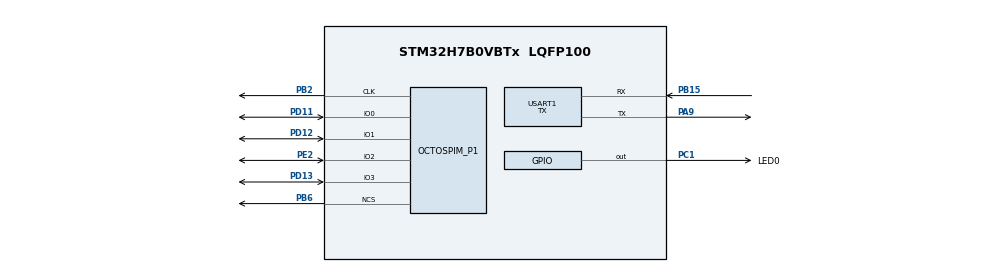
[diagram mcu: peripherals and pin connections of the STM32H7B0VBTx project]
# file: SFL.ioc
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CORTEX_M7.default_mode_Activation=1
Mcu.Family=STM32H7
Mcu.Name=STM32H7B0VBTx
Mcu.Package=LQFP100
NVIC.PriorityGroup=NVIC_PRIORITYGROUP_4
OCTOSPI1.ClockMode=HAL_OSPI_CLOCK_MODE_3
OCTOSPI1.ClockPrescaler=2
OCTOSPI1.DeviceSize=23
OCTOSPI1.FifoThreshold=8
OCTOSPI1.SampleShifting=HAL_OSPI_SAMPLE_SHIFTING_HALFCYCLE
PA13.Mode=Serial_Wire
PA13.Signal=DEBUG_JTMS-SWDIO
PA14.Mode=Serial_Wire
PA14.Signal=DEBUG_JTCK-SWCLK
PA9.Mode=Asynchronous
PA9.Signal=USART1_TX
PB15.Mode=Asynchronous
PB15.Signal=USART1_RX
PB2.Mode=O1_P1_CLK
PB2.Signal=OCTOSPIM_P1_CLK
PB6.Mode=OCTOSPI1_Port1_NCS
PB6.Signal=OCTOSPIM_P1_NCS
PC1.GPIO_Label=LED0
PC1.GPIO_Speed=GPIO_SPEED_FREQ_VERY_HIGH
PC1.PinState=GPIO_PIN_SET
PC1.Signal=GPIO_Output
PD11.Mode=OCTOSPI1_IOL_Port1L
PD11.Signal=OCTOSPIM_P1_IO0
PD12.Mode=OCTOSPI1_IOL_Port1L
PD12.Signal=OCTOSPIM_P1_IO1
PD13.Mode=OCTOSPI1_IOL_Port1L
PD13.Signal=OCTOSPIM_P1_IO3
PE2.Mode=OCTOSPI1_IOL_Port1L
PE2.Signal=OCTOSPIM_P1_IO2
PH0-OSC_IN.Mode=HSE-External-Oscillator
PH0-OSC_IN.Signal=RCC_OSC_IN
PH1-OSC_OUT.Mode=HSE-External-Oscillator
PH1-OSC_OUT.Signal=RCC_OSC_OUT
ProjectManager.HeapSize=0x200
ProjectManager.StackSize=0x400
ProjectManager.TargetToolchain=CMake
RCC.ADCFreq_Value=50390625
RCC.APB1Freq_Value=140000000
RCC.APB2Freq_Value=140000000
RCC.APB3Freq_Value=140000000
RCC.APB4Freq_Value=140000000
RCC.CDPPRE=RCC_APB3_DIV2
RCC.CDPPRE1=RCC_APB1_DIV2
RCC.CDPPRE2=RCC_APB2_DIV2
RCC.CortexFreq_Value=280000000
RCC.DIVM1=5
RCC.DIVN1=112
RCC.HCLKFreq_Value=280000000
RCC.HSE_VALUE=25000000
RCC.PLLSourceVirtual=RCC_PLLSOURCE_HSE
RCC.SRDPPRE=RCC_APB4_DIV2
RCC.SYSCLKFreq_VALUE=280000000
RCC.SYSCLKSource=RCC_SYSCLKSOURCE_PLLCLK
RCC.USBFreq_Value=280000000
USART1.Mode=MODE_TX
USART1.VirtualMode-Asynchronous=VM_ASYNC
VP_MEMORYMAP_VS_MEMORYMAP.Mode=CurAppReg
VP_OCTOSPI1_VS_octo.Mode=octo_mode
board=custom

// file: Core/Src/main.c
/* USER CODE BEGIN Header */
/**
  ******************************************************************************
  * @file           : main.c
  * @brief          : Main program body
  ******************************************************************************
  * @attention
  *
  * Copyright (c) 2026 STMicroelectronics.
  * All rights reserved.
  *
  * This software is licensed under terms that can be found in the LICENSE file
  * in the root directory of this software component.
  * If no LICENSE file comes with this software, it is provided AS-IS.
  *
  ******************************************************************************
  */
/* USER CODE END Header */
#include "main.h"
#include "octospi.h"
#include "usart.h"
#include "gpio.h"

/* USER CODE BEGIN Includes */
#include "ext_flash.h"
/* USER CODE END Includes */

/* USER CODE BEGIN PV */
#if (SFL_PROJECT == 0)
/* USER CODE END PV */

void SystemClock_Config(void);
static void MPU_Config(void);
/* USER CODE BEGIN PFP */
#endif
/* USER CODE END PFP */

int main(void)
{

  /* USER CODE BEGIN 1 */
  while (1) {
    ;
  }
  uint32_t start_tick = 0;
  /* USER CODE END 1 */

  /* MPU Configuration--------------------------------------------------------*/
  MPU_Config();

  /* MCU Configuration--------------------------------------------------------*/

  /* Reset of all peripherals, Initializes the Flash interface and the Systick. */
  HAL_Init();

  /* Configure the system clock */
  SystemClock_Config();

  /* Initialize all configured peripherals */
  MX_GPIO_Init();
  MX_OCTOSPI1_Init();
  MX_USART1_UART_Init();
  /* USER CODE BEGIN 2 */
  // OSPI_W25Qxx_Test();
  /* USER CODE END 2 */

  /* Infinite loop */
  /* USER CODE BEGIN WHILE */
  start_tick = HAL_GetTick();
  while (1)
  {
    /* USER CODE END WHILE */

    /* USER CODE BEGIN 3 */
    if(HAL_GetTick() - start_tick >= 500)
    {
      HAL_GPIO_TogglePin(LED0_GPIO_Port, LED0_Pin);
      start_tick = HAL_GetTick();
    }
  }
  /* USER CODE END 3 */
}

void SystemClock_Config(void)
{
  RCC_OscInitTypeDef RCC_OscInitStruct = {0};
  RCC_ClkInitTypeDef RCC_ClkInitStruct = {0};

  /*AXI clock gating */
  RCC->CKGAENR = 0xE003FFFF;

  /** Supply configuration update enable
  */
  HAL_PWREx_ConfigSupply(PWR_LDO_SUPPLY);

  /** Configure the main internal regulator output voltage
  */
  __HAL_PWR_VOLTAGESCALING_CONFIG(PWR_REGULATOR_VOLTAGE_SCALE0);

  while(!__HAL_PWR_GET_FLAG(PWR_FLAG_VOSRDY)) {}

  /** Initializes the RCC Oscillators according to the specified parameters
  * in the RCC_OscInitTypeDef structure.
  */
  RCC_OscInitStruct.OscillatorType = RCC_OSCILLATORTYPE_HSE;
  RCC_OscInitStruct.HSEState = RCC_HSE_ON;
  RCC_OscInitStruct.PLL.PLLState = RCC_PLL_ON;
  RCC_OscInitStruct.PLL.PLLSource = RCC_PLLSOURCE_HSE;
  RCC_OscInitStruct.PLL.PLLM = 5;
  RCC_OscInitStruct.PLL.PLLN = 112;
  RCC_OscInitStruct.PLL.PLLP = 2;
  RCC_OscInitStruct.PLL.PLLQ = 2;
  RCC_OscInitStruct.PLL.PLLR = 2;
  RCC_OscInitStruct.PLL.PLLRGE = RCC_PLL1VCIRANGE_2;
  RCC_OscInitStruct.PLL.PLLVCOSEL = RCC_PLL1VCOWIDE;
  RCC_OscInitStruct.PLL.PLLFRACN = 0;
  if (HAL_RCC_OscConfig(&RCC_OscInitStruct) != HAL_OK)
  {
    Error_Handler();
  }

  /** Initializes the CPU, AHB and APB buses clocks
  */
  RCC_ClkInitStruct.ClockType = RCC_CLOCKTYPE_HCLK|RCC_CLOCKTYPE_SYSCLK
                              |RCC_CLOCKTYPE_PCLK1|RCC_CLOCKTYPE_PCLK2
                              |RCC_CLOCKTYPE_D3PCLK1|RCC_CLOCKTYPE_D1PCLK1;
  RCC_ClkInitStruct.SYSCLKSource = RCC_SYSCLKSOURCE_PLLCLK;
  RCC_ClkInitStruct.SYSCLKDivider = RCC_SYSCLK_DIV1;
  RCC_ClkInitStruct.AHBCLKDivider = RCC_HCLK_DIV1;
  RCC_ClkInitStruct.APB3CLKDivider = RCC_APB3_DIV2;
  RCC_ClkInitStruct.APB1CLKDivider = RCC_APB1_DIV2;
  RCC_ClkInitStruct.APB2CLKDivider = RCC_APB2_DIV2;
  RCC_ClkInitStruct.APB4CLKDivider = RCC_APB4_DIV2;

  if (HAL_RCC_ClockConfig(&RCC_ClkInitStruct, FLASH_LATENCY_6) != HAL_OK)
  {
    Error_Handler();
  }
}

 /* MPU Configuration */

void MPU_Config(void)
{
  MPU_Region_InitTypeDef MPU_InitStruct = {0};

  /* Disables the MPU */
  HAL_MPU_Disable();

  /** Initializes and configures the Region and the memory to be protected
  */
  MPU_InitStruct.Enable = MPU_REGION_ENABLE;
  MPU_InitStruct.Number = MPU_REGION_NUMBER0;
  MPU_InitStruct.BaseAddress = 0x0;
  MPU_InitStruct.Size = MPU_REGION_SIZE_4GB;
  MPU_InitStruct.SubRegionDisable = 0x87;
  MPU_InitStruct.TypeExtField = MPU_TEX_LEVEL0;
  MPU_InitStruct.AccessPermission = MPU_REGION_NO_ACCESS;
  MPU_InitStruct.DisableExec = MPU_INSTRUCTION_ACCESS_DISABLE;
  MPU_InitStruct.IsShareable = MPU_ACCESS_SHAREABLE;
  MPU_InitStruct.IsCacheable = MPU_ACCESS_NOT_CACHEABLE;
  MPU_InitStruct.IsBufferable = MPU_ACCESS_NOT_BUFFERABLE;

  HAL_MPU_ConfigRegion(&MPU_InitStruct);
  /* Enables the MPU */
  HAL_MPU_Enable(MPU_PRIVILEGED_DEFAULT);

}

void Error_Handler(void)
{
  __disable_irq();
  while (1)
  {
  }
}
